AUTOSAR XML (schema 4-2-2)
package /ComponentTypes
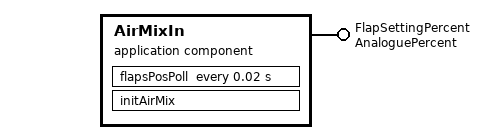
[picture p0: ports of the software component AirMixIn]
  application sw component type AirMixIn
    provide port FlapSettingPercent: nonqueued-sender-com-spec{data-element=flapSettingPercent, init-value=0}, provided-interface=AnaloguePercent
    behavior AirMixIn_InternalBehavior: data-type-mapping=flapMapSet
      timing event TMT_flapsPos: start-on-event=flapsPosPoll, period=0.02
      init event AirMixIn_InitEvent: start-on-event=initAirMix
      runnable flapsPosPoll
        data-send-points:
          access SEND_FlapSettingPercent_flapSettingPercent: accessed-variable=FlapSettingPercent.flapSettingPercent
      runnable initAirMix
        data-send-points:
          access SEND_FlapSettingPercent_flapSettingPercent: accessed-variable=FlapSettingPercent.flapSettingPercent
  swc implementation AirMixIn_Implementation: behavior=AirMixIn_InternalBehavior
